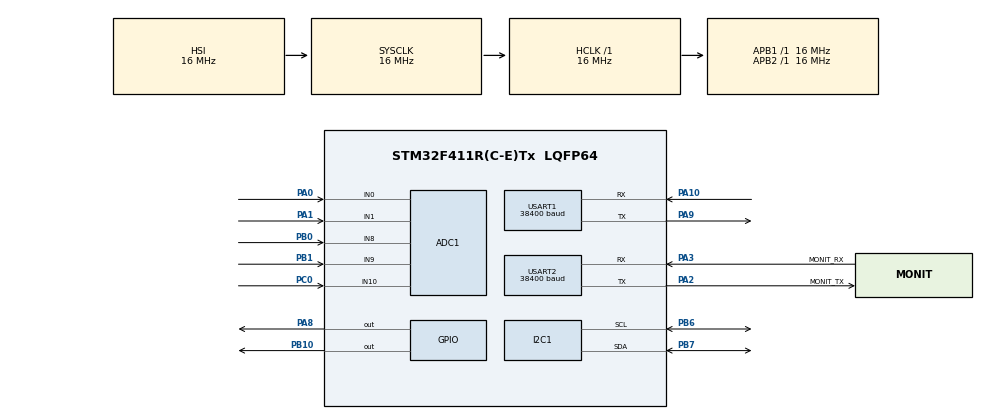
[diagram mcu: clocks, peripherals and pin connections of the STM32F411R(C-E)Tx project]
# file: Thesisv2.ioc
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ADC1.Channel-0\#ChannelRegularConversion=ADC_CHANNEL_0
ADC1.Channel-1\#ChannelRegularConversion=ADC_CHANNEL_1
ADC1.Channel-2\#ChannelRegularConversion=ADC_CHANNEL_8
ADC1.Channel-3\#ChannelRegularConversion=ADC_CHANNEL_9
ADC1.Channel-4\#ChannelRegularConversion=ADC_CHANNEL_10
ADC1.ClockPrescaler=ADC_CLOCK_SYNC_PCLK_DIV8
ADC1.ContinuousConvMode=ENABLE
ADC1.DMAContinuousRequests=ENABLE
ADC1.EnableAnalogWatchDog=false
ADC1.InjNumberOfConversion=0
ADC1.NbrOfConversion=5
ADC1.NbrOfConversionFlag=1
ADC1.Rank-0\#ChannelRegularConversion=1
ADC1.Rank-1\#ChannelRegularConversion=2
ADC1.Rank-2\#ChannelRegularConversion=3
ADC1.Rank-3\#ChannelRegularConversion=4
ADC1.Rank-4\#ChannelRegularConversion=5
ADC1.SamplingTime-0\#ChannelRegularConversion=ADC_SAMPLETIME_3CYCLES
ADC1.SamplingTime-1\#ChannelRegularConversion=ADC_SAMPLETIME_3CYCLES
ADC1.SamplingTime-2\#ChannelRegularConversion=ADC_SAMPLETIME_3CYCLES
ADC1.SamplingTime-3\#ChannelRegularConversion=ADC_SAMPLETIME_3CYCLES
ADC1.SamplingTime-4\#ChannelRegularConversion=ADC_SAMPLETIME_3CYCLES
ADC1.ScanConvMode=ENABLE
ADC1.master=1
Dma.ADC1.0.Direction=DMA_PERIPH_TO_MEMORY
Dma.ADC1.0.FIFOMode=DMA_FIFOMODE_ENABLE
Dma.ADC1.0.FIFOThreshold=DMA_FIFO_THRESHOLD_FULL
Dma.ADC1.0.Instance=DMA2_Stream0
Dma.ADC1.0.MemBurst=DMA_MBURST_SINGLE
Dma.ADC1.0.MemDataAlignment=DMA_MDATAALIGN_HALFWORD
Dma.ADC1.0.MemInc=DMA_MINC_ENABLE
Dma.ADC1.0.Mode=DMA_CIRCULAR
Dma.ADC1.0.PeriphBurst=DMA_PBURST_SINGLE
Dma.ADC1.0.PeriphDataAlignment=DMA_PDATAALIGN_HALFWORD
Dma.ADC1.0.PeriphInc=DMA_PINC_DISABLE
Dma.ADC1.0.Priority=DMA_PRIORITY_HIGH
Dma.I2C1_RX.1.Direction=DMA_PERIPH_TO_MEMORY
Dma.I2C1_RX.1.FIFOMode=DMA_FIFOMODE_DISABLE
Dma.I2C1_RX.1.Instance=DMA1_Stream0
Dma.I2C1_RX.1.MemDataAlignment=DMA_MDATAALIGN_BYTE
Dma.I2C1_RX.1.MemInc=DMA_MINC_ENABLE
Dma.I2C1_RX.1.Mode=DMA_NORMAL
Dma.I2C1_RX.1.PeriphDataAlignment=DMA_PDATAALIGN_BYTE
Dma.I2C1_RX.1.PeriphInc=DMA_PINC_DISABLE
Dma.I2C1_RX.1.Priority=DMA_PRIORITY_HIGH
Dma.Request0=ADC1
Dma.Request1=I2C1_RX
Dma.Request2=USART2_TX
Dma.Request3=USART1_TX
Dma.Request4=USART1_RX
Dma.USART1_RX.4.Direction=DMA_PERIPH_TO_MEMORY
Dma.USART1_RX.4.FIFOMode=DMA_FIFOMODE_DISABLE
Dma.USART1_RX.4.Instance=DMA2_Stream2
Dma.USART1_RX.4.MemDataAlignment=DMA_MDATAALIGN_BYTE
Dma.USART1_RX.4.MemInc=DMA_MINC_ENABLE
Dma.USART1_RX.4.Mode=DMA_NORMAL
Dma.USART1_RX.4.PeriphDataAlignment=DMA_PDATAALIGN_BYTE
Dma.USART1_RX.4.PeriphInc=DMA_PINC_DISABLE
Dma.USART1_RX.4.Priority=DMA_PRIORITY_MEDIUM
Dma.USART1_TX.3.Direction=DMA_MEMORY_TO_PERIPH
Dma.USART1_TX.3.FIFOMode=DMA_FIFOMODE_DISABLE
Dma.USART1_TX.3.Instance=DMA2_Stream7
Dma.USART1_TX.3.MemDataAlignment=DMA_MDATAALIGN_BYTE
Dma.USART1_TX.3.MemInc=DMA_MINC_ENABLE
Dma.USART1_TX.3.Mode=DMA_NORMAL
Dma.USART1_TX.3.PeriphDataAlignment=DMA_PDATAALIGN_BYTE
Dma.USART1_TX.3.PeriphInc=DMA_PINC_DISABLE
Dma.USART1_TX.3.Priority=DMA_PRIORITY_MEDIUM
Dma.USART2_TX.2.Direction=DMA_MEMORY_TO_PERIPH
Dma.USART2_TX.2.FIFOMode=DMA_FIFOMODE_DISABLE
Dma.USART2_TX.2.Instance=DMA1_Stream6
Dma.USART2_TX.2.MemDataAlignment=DMA_MDATAALIGN_BYTE
Dma.USART2_TX.2.MemInc=DMA_MINC_ENABLE
Dma.USART2_TX.2.Mode=DMA_NORMAL
Dma.USART2_TX.2.PeriphDataAlignment=DMA_PDATAALIGN_BYTE
Dma.USART2_TX.2.PeriphInc=DMA_PINC_DISABLE
Dma.USART2_TX.2.Priority=DMA_PRIORITY_MEDIUM
Mcu.Family=STM32F4
Mcu.Name=STM32F411R(C-E)Tx
Mcu.Package=LQFP64
NVIC.DMA1_Stream0_IRQn=true\:2\:0\:true\:false\:true\:false\:true\:true
NVIC.DMA1_Stream6_IRQn=true\:0\:0\:false\:false\:true\:false\:true\:true
NVIC.DMA2_Stream0_IRQn=true\:2\:0\:true\:false\:true\:false\:true\:true
NVIC.DMA2_Stream2_IRQn=true\:0\:0\:false\:false\:true\:false\:true\:true
NVIC.DMA2_Stream7_IRQn=true\:1\:0\:true\:false\:true\:false\:true\:true
NVIC.I2C1_ER_IRQn=true\:1\:0\:true\:false\:true\:true\:true\:true
NVIC.I2C1_EV_IRQn=true\:1\:0\:true\:false\:true\:true\:true\:true
NVIC.PriorityGroup=NVIC_PRIORITYGROUP_4
NVIC.TIM2_IRQn=true\:0\:0\:true\:false\:true\:true\:true\:true
NVIC.TIM3_IRQn=true\:0\:0\:false\:false\:true\:true\:true\:true
NVIC.USART1_IRQn=true\:2\:0\:true\:false\:true\:true\:true\:true
NVIC.USART2_IRQn=true\:2\:0\:true\:true\:true\:1\:true\:true\:true
PA0-WKUP.Signal=ADCx_IN0
PA1.Signal=ADCx_IN1
PA10.Mode=Asynchronous
PA10.Signal=USART1_RX
PA2.GPIO_Label=MONIT_TX
PA2.Mode=Asynchronous
PA2.Signal=USART2_TX
PA3.GPIO_Label=MONIT_RX
PA3.Mode=Asynchronous
PA3.Signal=USART2_RX
PA8.Signal=GPIO_Output
PA9.Mode=Asynchronous
PA9.Signal=USART1_TX
PB0.Signal=ADCx_IN8
PB1.Signal=ADCx_IN9
PB10.GPIO_PuPd=GPIO_PULLDOWN
PB10.PinState=GPIO_PIN_SET
PB10.Signal=GPIO_Output
PB6.Mode=I2C
PB6.Signal=I2C1_SCL
PB7.Mode=I2C
PB7.Signal=I2C1_SDA
PC0.Signal=ADCx_IN10
PH0\ -\ OSC_IN.Mode=HSE-External-Oscillator
PH0\ -\ OSC_IN.Signal=RCC_OSC_IN
PH1\ -\ OSC_OUT.Mode=HSE-External-Oscillator
PH1\ -\ OSC_OUT.Signal=RCC_OSC_OUT
ProjectManager.HeapSize=0x200
ProjectManager.StackSize=0x400
ProjectManager.TargetToolchain=STM32CubeIDE
RCC.48MHZClocksFreq_Value=52083333.33333333
RCC.AHBFreq_Value=16000000
RCC.APB1Freq_Value=16000000
RCC.APB1TimFreq_Value=16000000
RCC.APB2Freq_Value=16000000
RCC.APB2TimFreq_Value=16000000
RCC.CortexFreq_Value=16000000
RCC.HCLKFreq_Value=16000000
RCC.HSE_VALUE=25000000
RCC.HSI_VALUE=16000000
RCC.LSE_VALUE=32768
RCC.PLLM=6
RCC.PLLN=50
RCC.PLLP=RCC_PLLP_DIV8
RCC.PLLSourceVirtual=RCC_PLLSOURCE_HSE
RCC.SYSCLKFreq_VALUE=16000000
RCC.VCOOutputFreq_Value=208333333.3333333
SH.ADCx_IN0.0=ADC1_IN0,IN0
SH.ADCx_IN1.0=ADC1_IN1,IN1
SH.ADCx_IN10.0=ADC1_IN10,IN10
SH.ADCx_IN8.0=ADC1_IN8,IN8
SH.ADCx_IN9.0=ADC1_IN9,IN9
TIM2.Period=9999
TIM2.Prescaler=39
TIM3.Period=7999
TIM3.Prescaler=999
USART1.BaudRate=38400
USART1.VirtualMode=VM_ASYNC
USART2.BaudRate=38400
USART2.Mode=MODE_TX
USART2.Parity=PARITY_NONE
USART2.VirtualMode=VM_ASYNC
USART2.WordLength=WORDLENGTH_8B
VP_CRC_VS_CRC.Mode=CRC_Activate
VP_RTC_VS_RTC_Activate.Mode=RTC_Enabled
VP_TIM2_VS_ClockSourceINT.Mode=Internal
VP_TIM3_VS_ClockSourceINT.Mode=Internal
board=custom

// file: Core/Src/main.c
/* USER CODE BEGIN Header */
/**
  ******************************************************************************
  * @file           : main.c
  * @brief          : Main program body
  ******************************************************************************
  * @attention
  *
  * Copyright (c) 2023 STMicroelectronics.
  * All rights reserved.
  *
  * This software is licensed under terms that can be found in the LICENSE file
  * in the root directory of this software component.
  * If no LICENSE file comes with this software, it is provided AS-IS.
  *
  ******************************************************************************
  */
/* USER CODE END Header */
#include "main.h"
#include "adc.h"
#include "crc.h"
#include "dma.h"
#include "i2c.h"
#include "rtc.h"
#include "tim.h"
#include "usart.h"
#include "gpio.h"

/* USER CODE BEGIN Includes */
#include "accelerometre.h"
#include "kalman.h"
#include "bluetooth_module.h"
#include "timers.h"
/* USER CODE END Includes */

/* USER CODE BEGIN PD */
#define FINGERS_AMOUNT 5
/* USER CODE END PD */

/* USER CODE BEGIN PV */
volatile uint16_t pot_variables[FINGERS_AMOUNT] = {0,0,0,0,0};

/* USER CODE END PV */

void SystemClock_Config(void);
static void MX_NVIC_Init(void);

int main(void)
{

  /* MCU Configuration--------------------------------------------------------*/

  /* Reset of all peripherals, Initializes the Flash interface and the Systick. */
  HAL_Init();

  /* Configure the system clock */
  SystemClock_Config();

  /* Initialize all configured peripherals */
  MX_GPIO_Init();
  MX_DMA_Init();
  MX_ADC1_Init();
  MX_RTC_Init();
  MX_USART2_UART_Init();
  MX_I2C1_Init();
  MX_TIM2_Init();
  MX_CRC_Init();
  MX_USART1_UART_Init();
  MX_TIM3_Init();

  /* Initialize interrupts */
  MX_NVIC_Init();
  /* USER CODE BEGIN 2 */
   enable_BluetoothEditMode(&bt_editMode);
   calculate_Tim2Period();
   accel_Init();
   HAL_TIM_Base_Start_IT(&htim2);
   HAL_TIM_Base_Start_IT(&htim3);
   HAL_ADC_Start_DMA(&hadc1,(uint32_t*)pot_variables, FINGERS_AMOUNT);
   HAL_UART_Receive_DMA(&huart1, bluetooth_RX1_buffer, BUFF_LEN);
 /*  set_bluetooth_Name();
   HAL_Delay(1000);
   check_Bluetooth();
   HAL_Delay(1000);
   check_bluetooth_Name();
   HAL_Delay(1000);
   check_bluetooth_BaudRate();
   HAL_Delay(1000);
   HAL_Delay(1000);*/

  /* USER CODE END 2 */

  /* Infinite loop */
  while (1)
  {

	    check_bluetooth_Name();
	    HAL_Delay(1000);
	    set_bluetooth_Name();
	    HAL_Delay(1000);

  }
}

void SystemClock_Config(void)
{
  RCC_OscInitTypeDef RCC_OscInitStruct = {0};
  RCC_ClkInitTypeDef RCC_ClkInitStruct = {0};

  /** Configure the main internal regulator output voltage
  */
  __HAL_RCC_PWR_CLK_ENABLE();
  __HAL_PWR_VOLTAGESCALING_CONFIG(PWR_REGULATOR_VOLTAGE_SCALE1);

  /** Initializes the RCC Oscillators according to the specified parameters
  * in the RCC_OscInitTypeDef structure.
  */
  RCC_OscInitStruct.OscillatorType = RCC_OSCILLATORTYPE_HSI|RCC_OSCILLATORTYPE_LSI;
  RCC_OscInitStruct.HSIState = RCC_HSI_ON;
  RCC_OscInitStruct.HSICalibrationValue = RCC_HSICALIBRATION_DEFAULT;
  RCC_OscInitStruct.LSIState = RCC_LSI_ON;
  RCC_OscInitStruct.PLL.PLLState = RCC_PLL_NONE;
  if (HAL_RCC_OscConfig(&RCC_OscInitStruct) != HAL_OK)
  {
    Error_Handler();
  }

  /** Initializes the CPU, AHB and APB buses clocks
  */
  RCC_ClkInitStruct.ClockType = RCC_CLOCKTYPE_HCLK|RCC_CLOCKTYPE_SYSCLK
                              |RCC_CLOCKTYPE_PCLK1|RCC_CLOCKTYPE_PCLK2;
  RCC_ClkInitStruct.SYSCLKSource = RCC_SYSCLKSOURCE_HSI;
  RCC_ClkInitStruct.AHBCLKDivider = RCC_SYSCLK_DIV1;
  RCC_ClkInitStruct.APB1CLKDivider = RCC_HCLK_DIV1;
  RCC_ClkInitStruct.APB2CLKDivider = RCC_HCLK_DIV1;

  if (HAL_RCC_ClockConfig(&RCC_ClkInitStruct, FLASH_LATENCY_0) != HAL_OK)
  {
    Error_Handler();
  }
}

/**
  * @brief NVIC Configuration.
  * @retval None
  */
static void MX_NVIC_Init(void)
{
  /* USART2_IRQn interrupt configuration */
  HAL_NVIC_SetPriority(USART2_IRQn, 2, 0);
  HAL_NVIC_EnableIRQ(USART2_IRQn);
}

void Error_Handler(void)
{
  __disable_irq();
  while (1)
  {
  }
}
